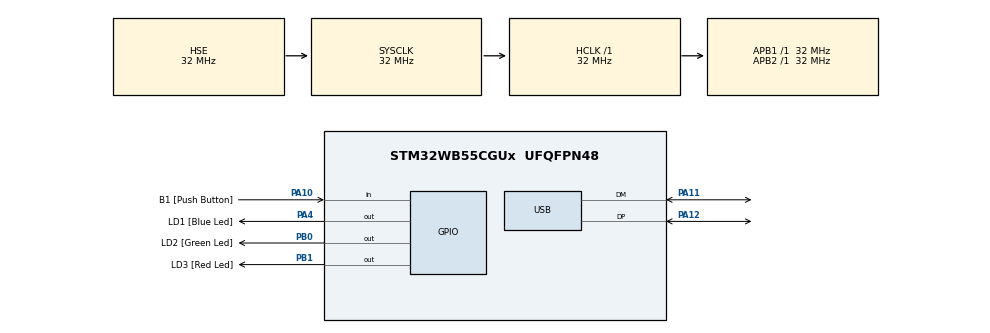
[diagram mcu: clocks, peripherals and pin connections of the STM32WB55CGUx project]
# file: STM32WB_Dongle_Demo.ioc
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Mcu.Family=STM32WB
RCC.CortexFreq_Value=32000000
RF1.Signal=RF_RF1
PA14.GPIO_Label=JTCK
VP_RTC_VS_RTC_Activate.Mode=RTC_Enabled
PA11.Mode=Device
PB0.GPIO_Label=LD2 [Green Led]
RCC.SYSCLKSource=RCC_SYSCLKSOURCE_HSE
ProjectManager.StackSize=0x400
PA12.Signal=USB_DP
RCC.HCLKFreq_Value=32000000
STM32_WPAN.LOCAL_NAME=NEXOTRO
RCC.APB2TimFreq_Value=32000000
OSC_OUT.Mode=HSE-External-Oscillator
OSC_OUT.Signal=RCC_OSC_OUT
RCC.AHBFreq_Value=32000000
RCC.HSE_VALUE=32000000
RCC.RTCClockSelection=RCC_RTCCLKSOURCE_LSE
PC14-OSC32_IN.Mode=LSE-External-Oscillator
PA14.Mode=Serial_Wire
PB1.GPIO_Label=LD3 [Red Led]
PA10.GPIO_Label=B1 [Push Button]
RCC.APB3Freq_Value=16000000
NVIC.HSEM_IRQn=true\:0\:0\:false\:false\:true\:false\:true
Mcu.Package=UFQFPN48
PB1.Signal=GPIO_Output
PA10.Signal=GPIO_Input
VP_TINY_LPM_VS_TINY_LPM.Mode=TINY_LPM_Enabled
VP_HSEM_VS_HSEM.Mode=HSEM_Activate
RCC.APB1TimFreq_Value=32000000
RCC.SMPSDivider=1
PA4.GPIO_Label=LD1 [Blue Led]
RCC.HSI48_VALUE=48000000
RCC.PLLSAI1N=24
PB3.GPIO_Label=JTDO
PC15-OSC32_OUT.Mode=LSE-External-Oscillator
VP_STM32_WPAN_VS_BLE_HOST.Mode=STM32_WPAN_Enabled
STM32_WPAN.BLE_APPLICATION_TYPE=BLE_SERVER_PROFILE
VP_RNG_VS_RNG.Mode=RNG_Activate
PC14-OSC32_IN.Signal=RCC_OSC32_IN
PA13.Signal=SYS_JTMS-SWDIO
ProjectManager.TargetToolchain=EWARM V8.32
STM32_WPAN.LOCAL_NAME_FORMATTED=,'N','E','X','O','T','R','O'
OSC_IN.Signal=RCC_OSC_IN
RCC.USBFreq_Value=48000000
PC15-OSC32_OUT.Signal=RCC_OSC32_OUT
board=P-NUCLEO-WB55-USBDongle
VP_SEQUENCER_VS_SEQUENCER.Mode=SEQUENCER_Enabled
RCC.VCOOutputFreq_Value=96000000
RCC.APB2Freq_Value=32000000
RCC.ADCFreq_Value=48000000
STM32_WPAN.BT_SIG_BEACON=Enabled
PA13.Mode=Serial_Wire
Mcu.Name=STM32WB55CGUx
PA13.GPIO_Label=JTMS
PB3.Signal=SYS_JTDO-SWO
PA4.Signal=GPIO_Output
RCC.SYSCLKFreq_VALUE=32000000
PA12.Mode=Device
OSC_IN.Mode=HSE-External-Oscillator
RF1.Mode=RF1_Activate
PA11.Signal=USB_DM
PA14.Signal=SYS_JTCK-SWCLK
ProjectManager.HeapSize=0x200
RCC.HSI_VALUE=16000000
NVIC.PriorityGroup=NVIC_PRIORITYGROUP_4
RCC.PLLR=RCC_PLLR_DIV3
RCC.PLLN=24
RCC.APB1Freq_Value=32000000
RCC.RFWKPClockSelection=RCC_RFWKPCLKSOURCE_LSE
VP_CRC_VS_CRC.Mode=CRC_Activate
PB0.Signal=GPIO_Output

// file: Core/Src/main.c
/* USER CODE BEGIN Header */
/**
  ******************************************************************************
  * @file           : main.c
  * @brief          : Main program body
  ******************************************************************************
  * @attention
  *
  * <h2><center>&copy; Copyright (c) 2020 STMicroelectronics.
  * All rights reserved.</center></h2>
  *
  * This software component is licensed by ST under Ultimate Liberty license
  * SLA0044, the "License"; You may not use this file except in compliance with
  * the License. You may obtain a copy of the License at:
  *                             www.st.com/SLA0044
  *
  ******************************************************************************
  */
/* USER CODE END Header */
#include "main.h"
#include "app_entry.h"
#include "app_common.h"

/* USER CODE BEGIN Includes */
#include "stm32_lpm.h"
#include "stm32_seq.h"
#include "dbg_trace.h"
/* USER CODE END Includes */

CRC_HandleTypeDef hcrc;

RNG_HandleTypeDef hrng;

RTC_HandleTypeDef hrtc;

PCD_HandleTypeDef hpcd_USB_FS;

void SystemClock_Config(void);
static void MX_GPIO_Init(void);
static void MX_CRC_Init(void);
static void MX_RF_Init(void);
static void MX_RNG_Init(void);
static void MX_RTC_Init(void);
static void MX_USB_PCD_Init(void);

int main(void)
{

  /* MCU Configuration--------------------------------------------------------*/

  /* Reset of all peripherals, Initializes the Flash interface and the Systick. */
  HAL_Init();

  /* Configure the system clock */
  SystemClock_Config();

  /* Initialize all configured peripherals */
  MX_GPIO_Init();
  MX_CRC_Init();
  MX_RF_Init();
  MX_RNG_Init();
  MX_RTC_Init();
  MX_USB_PCD_Init();

  /* Init code for STM32_WPAN */
  APPE_Init();
  /* Infinite loop */
  /* USER CODE BEGIN WHILE */
  while (1)
  {
    UTIL_SEQ_Run( UTIL_SEQ_DEFAULT );
    /* USER CODE END WHILE */

  }
}

void SystemClock_Config(void)
{
  RCC_OscInitTypeDef RCC_OscInitStruct = {0};
  RCC_ClkInitTypeDef RCC_ClkInitStruct = {0};
  RCC_PeriphCLKInitTypeDef PeriphClkInitStruct = {0};

  /** Macro to configure the PLL multiplication factor
  */
  __HAL_RCC_PLL_PLLM_CONFIG(RCC_PLLM_DIV1);
  /** Macro to configure the PLL clock source
  */
  __HAL_RCC_PLL_PLLSOURCE_CONFIG(RCC_PLLSOURCE_MSI);
  /** Configure LSE Drive Capability
  */
  HAL_PWR_EnableBkUpAccess();
  __HAL_RCC_LSEDRIVE_CONFIG(RCC_LSEDRIVE_LOW);
  /** Configure the main internal regulator output voltage
  */
  __HAL_PWR_VOLTAGESCALING_CONFIG(PWR_REGULATOR_VOLTAGE_SCALE1);
  /** Initializes the RCC Oscillators according to the specified parameters
  * in the RCC_OscInitTypeDef structure.
  */
  RCC_OscInitStruct.OscillatorType = RCC_OSCILLATORTYPE_HSI|RCC_OSCILLATORTYPE_LSI1
                              |RCC_OSCILLATORTYPE_HSE|RCC_OSCILLATORTYPE_LSE
                              |RCC_OSCILLATORTYPE_MSI;
  RCC_OscInitStruct.HSEState = RCC_HSE_ON;
  RCC_OscInitStruct.LSEState = RCC_LSE_ON;
  RCC_OscInitStruct.HSIState = RCC_HSI_ON;
  RCC_OscInitStruct.MSIState = RCC_MSI_ON;
  RCC_OscInitStruct.HSICalibrationValue = RCC_HSICALIBRATION_DEFAULT;
  RCC_OscInitStruct.MSICalibrationValue = RCC_MSICALIBRATION_DEFAULT;
  RCC_OscInitStruct.MSIClockRange = RCC_MSIRANGE_6;
  RCC_OscInitStruct.LSIState = RCC_LSI_ON;
  RCC_OscInitStruct.PLL.PLLState = RCC_PLL_NONE;
  if (HAL_RCC_OscConfig(&RCC_OscInitStruct) != HAL_OK)
  {
    Error_Handler();
  }
  /** Configure the SYSCLKSource, HCLK, PCLK1 and PCLK2 clocks dividers
  */
  RCC_ClkInitStruct.ClockType = RCC_CLOCKTYPE_HCLK4|RCC_CLOCKTYPE_HCLK2
                              |RCC_CLOCKTYPE_HCLK|RCC_CLOCKTYPE_SYSCLK
                              |RCC_CLOCKTYPE_PCLK1|RCC_CLOCKTYPE_PCLK2;
  RCC_ClkInitStruct.SYSCLKSource = RCC_SYSCLKSOURCE_HSE;
  RCC_ClkInitStruct.AHBCLKDivider = RCC_SYSCLK_DIV1;
  RCC_ClkInitStruct.APB1CLKDivider = RCC_HCLK_DIV1;
  RCC_ClkInitStruct.APB2CLKDivider = RCC_HCLK_DIV1;
  RCC_ClkInitStruct.AHBCLK2Divider = RCC_SYSCLK_DIV1;
  RCC_ClkInitStruct.AHBCLK4Divider = RCC_SYSCLK_DIV1;

  if (HAL_RCC_ClockConfig(&RCC_ClkInitStruct, FLASH_LATENCY_1) != HAL_OK)
  {
    Error_Handler();
  }
  /** Initializes the peripherals clocks
  */
  PeriphClkInitStruct.PeriphClockSelection = RCC_PERIPHCLK_SMPS|RCC_PERIPHCLK_RFWAKEUP
                              |RCC_PERIPHCLK_RTC|RCC_PERIPHCLK_USB
                              |RCC_PERIPHCLK_RNG;
  PeriphClkInitStruct.PLLSAI1.PLLN = 24;
  PeriphClkInitStruct.PLLSAI1.PLLP = RCC_PLLP_DIV2;
  PeriphClkInitStruct.PLLSAI1.PLLQ = RCC_PLLQ_DIV2;
  PeriphClkInitStruct.PLLSAI1.PLLR = RCC_PLLR_DIV2;
  PeriphClkInitStruct.PLLSAI1.PLLSAI1ClockOut = RCC_PLLSAI1_USBCLK;
  PeriphClkInitStruct.UsbClockSelection = RCC_USBCLKSOURCE_PLLSAI1;
  PeriphClkInitStruct.RngClockSelection = RCC_RNGCLKSOURCE_LSI;
  PeriphClkInitStruct.RTCClockSelection = RCC_RTCCLKSOURCE_LSE;
  PeriphClkInitStruct.RFWakeUpClockSelection = RCC_RFWKPCLKSOURCE_LSE;
  PeriphClkInitStruct.SmpsClockSelection = RCC_SMPSCLKSOURCE_HSI;
  PeriphClkInitStruct.SmpsDivSelection = RCC_SMPSCLKDIV_RANGE0;
  if (HAL_RCCEx_PeriphCLKConfig(&PeriphClkInitStruct) != HAL_OK)
  {
    Error_Handler();
  }
  /** Enable MSI Auto calibration
  */
  HAL_RCCEx_EnableMSIPLLMode();
}

static void MX_CRC_Init(void)
{

  hcrc.Instance = CRC;
  hcrc.Init.DefaultPolynomialUse = DEFAULT_POLYNOMIAL_ENABLE;
  hcrc.Init.DefaultInitValueUse = DEFAULT_INIT_VALUE_ENABLE;
  hcrc.Init.InputDataInversionMode = CRC_INPUTDATA_INVERSION_NONE;
  hcrc.Init.OutputDataInversionMode = CRC_OUTPUTDATA_INVERSION_DISABLE;
  hcrc.InputDataFormat = CRC_INPUTDATA_FORMAT_BYTES;
  if (HAL_CRC_Init(&hcrc) != HAL_OK)
  {
    Error_Handler();
  }

}

static void MX_RF_Init(void)
{

}

static void MX_RNG_Init(void)
{

  hrng.Instance = RNG;
  if (HAL_RNG_Init(&hrng) != HAL_OK)
  {
    Error_Handler();
  }

}

static void MX_RTC_Init(void)
{

  /** Initialize RTC Only
  */
  hrtc.Instance = RTC;
  hrtc.Init.HourFormat = RTC_HOURFORMAT_24;
  hrtc.Init.AsynchPrediv = CFG_RTC_ASYNCH_PRESCALER;
  hrtc.Init.SynchPrediv = CFG_RTC_SYNCH_PRESCALER;
  hrtc.Init.OutPut = RTC_OUTPUT_DISABLE;
  hrtc.Init.OutPutPolarity = RTC_OUTPUT_POLARITY_HIGH;
  hrtc.Init.OutPutType = RTC_OUTPUT_TYPE_OPENDRAIN;
  hrtc.Init.OutPutRemap = RTC_OUTPUT_REMAP_NONE;
  if (HAL_RTC_Init(&hrtc) != HAL_OK)
  {
    Error_Handler();
  }

}

static void MX_USB_PCD_Init(void)
{

  hpcd_USB_FS.Instance = USB;
  hpcd_USB_FS.Init.dev_endpoints = 8;
  hpcd_USB_FS.Init.speed = PCD_SPEED_FULL;
  hpcd_USB_FS.Init.phy_itface = PCD_PHY_EMBEDDED;
  hpcd_USB_FS.Init.Sof_enable = DISABLE;
  hpcd_USB_FS.Init.low_power_enable = DISABLE;
  hpcd_USB_FS.Init.lpm_enable = DISABLE;
  hpcd_USB_FS.Init.battery_charging_enable = DISABLE;
  if (HAL_PCD_Init(&hpcd_USB_FS) != HAL_OK)
  {
    Error_Handler();
  }

}

static void MX_GPIO_Init(void)
{
  GPIO_InitTypeDef GPIO_InitStruct = {0};

  /* GPIO Ports Clock Enable */
  __HAL_RCC_GPIOC_CLK_ENABLE();
  __HAL_RCC_GPIOA_CLK_ENABLE();
  __HAL_RCC_GPIOB_CLK_ENABLE();

  /*Configure GPIO pin Output Level */
  HAL_GPIO_WritePin(LD1_GPIO_Port, LD1_Pin, GPIO_PIN_RESET);

  /*Configure GPIO pin Output Level */
  HAL_GPIO_WritePin(GPIOB, LD2_Pin|LD3_Pin, GPIO_PIN_RESET);

  /*Configure GPIO pin : LD1_Pin */
  GPIO_InitStruct.Pin = LD1_Pin;
  GPIO_InitStruct.Mode = GPIO_MODE_OUTPUT_PP;
  GPIO_InitStruct.Pull = GPIO_NOPULL;
  GPIO_InitStruct.Speed = GPIO_SPEED_FREQ_LOW;
  HAL_GPIO_Init(LD1_GPIO_Port, &GPIO_InitStruct);

  /*Configure GPIO pins : LD2_Pin LD3_Pin */
  GPIO_InitStruct.Pin = LD2_Pin|LD3_Pin;
  GPIO_InitStruct.Mode = GPIO_MODE_OUTPUT_PP;
  GPIO_InitStruct.Pull = GPIO_NOPULL;
  GPIO_InitStruct.Speed = GPIO_SPEED_FREQ_LOW;
  HAL_GPIO_Init(GPIOB, &GPIO_InitStruct);

  /*Configure GPIO pin : B1_Pin */
  GPIO_InitStruct.Pin = B1_Pin;
  GPIO_InitStruct.Mode = GPIO_MODE_INPUT;
  GPIO_InitStruct.Pull = GPIO_NOPULL;
  HAL_GPIO_Init(B1_GPIO_Port, &GPIO_InitStruct);

}

void Error_Handler(void)
{
}

/************************ (C) COPYRIGHT STMicroelectronics *****END OF FILE****/
